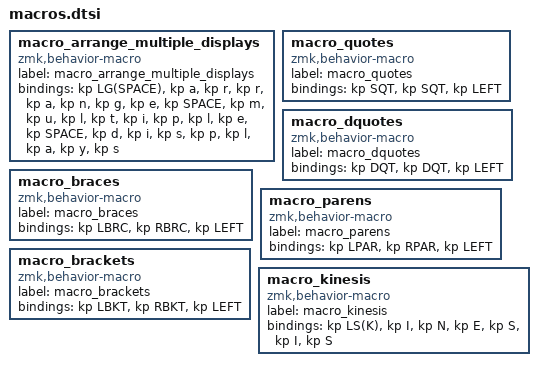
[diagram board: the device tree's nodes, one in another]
macro_arrange_multiple_displays: macro_arrange_multiple_displays{
compatible = "zmk,behavior-macro";
label = "macro_arrange_multiple_displays";
#binding-cells = <0>;
bindings = <&kp LG(SPACE)>, <&kp a>, <&kp r>, <&kp r>, <&kp a>, <&kp n>, <&kp g>, <&kp e>, <&kp SPACE>, <&kp m>, <&kp u>, <&kp l>, <&kp t>, <&kp i>, <&kp p>, <&kp l>, <&kp e>, <&kp SPACE>, <&kp d>, <&kp i>, <&kp s>, <&kp p>, <&kp l>, <&kp a>, <&kp y>, <&kp s>;
};
macro_quotes: macro_quotes{
compatible = "zmk,behavior-macro";
label = "macro_quotes";
#binding-cells = <0>;
bindings = <&kp SQT>, <&kp SQT>, <&kp LEFT>;
};
macro_dquotes: macro_dquotes{
compatible = "zmk,behavior-macro";
label = "macro_dquotes";
#binding-cells = <0>;
bindings = <&kp DQT>, <&kp DQT>, <&kp LEFT>;
};
macro_braces: macro_braces{
compatible = "zmk,behavior-macro";
label = "macro_braces";
#binding-cells = <0>;
bindings = <&kp LBRC>, <&kp RBRC>, <&kp LEFT>;
};
macro_parens: macro_parens{
compatible = "zmk,behavior-macro";
label = "macro_parens";
#binding-cells = <0>;
bindings = <&kp LPAR>, <&kp RPAR>, <&kp LEFT>;
};
macro_brackets: macro_brackets{
compatible = "zmk,behavior-macro";
label = "macro_brackets";
#binding-cells = <0>;
bindings = <&kp LBKT>, <&kp RBKT>, <&kp LEFT>;
};
macro_kinesis: macro_kinesis{
compatible = "zmk,behavior-macro";
label = "macro_kinesis";
#binding-cells = <0>;
bindings = <&kp LS(K)>, <&kp I>, <&kp N>, <&kp E>, <&kp S>, <&kp I>, <&kp S>;
};
